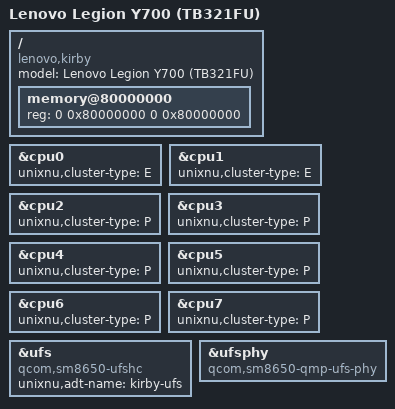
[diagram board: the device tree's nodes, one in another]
/dts-v1/;
/include/ "sm8650.dtsi"

/*
 * Lenovo Legion Y700 (TB321FU) — SM8650 / pineapple / kirby.
 *
 * sm8650.dtsi (devices/UniXNU-sm8650-common/dts) already carries the eight
 * CPUs with timebase-frequency, PSCI and the GIC.  This file adds only what is
 * board specific, so devicetree.generate() can build the ADT sidecar.
 *
 * DRAM: base 0x80000000, size 0x80000000 (2 GiB handoff window).
 *   - board.toml [payload] dram_size = "0x80000000"; generate() rejects a DTS
 *     that disagrees with it.
 *   - MemoryMapLib.c:55 puts the gunyah_hyp reserve at 0x80000000, i.e. the
 *     real start of DRAM rather than an arbitrary number.
 *   - The value is inherited from caihong (same SoC, same IPSW), not guessed.
 */
/ {
    model = "Lenovo Legion Y700 (TB321FU)";
    compatible = "lenovo,kirby", "qcom,sm8650";

    memory@80000000 {
        device_type = "memory";
        reg = <0 0x80000000 0 0x80000000>;
    };
};

/*
 * XNU reads cluster-type as an integer character.  A520 pair is efficiency;
 * the A720 triples and the X4 are performance.  Frequencies and capacities
 * behind that split are recorded at the top of sm8650.dtsi.
 */
&cpu0 { unixnu,cluster-type = "E"; };
&cpu1 { unixnu,cluster-type = "E"; };

&cpu2 { unixnu,cluster-type = "P"; };
&cpu3 { unixnu,cluster-type = "P"; };
&cpu4 { unixnu,cluster-type = "P"; };
&cpu5 { unixnu,cluster-type = "P"; };
&cpu6 { unixnu,cluster-type = "P"; };
&cpu7 { unixnu,cluster-type = "P"; };

/*
 * UFS —— 存储，也是根卷的载体。
 *
 * sm8650.dtsi 里 ufshc@1d84000 和 phy@1d80000 都是 status = "disabled"，
 * 而 devicetree.generate() 只把 enabled 且带 unixnu,adt-name 的节点写进 ADT
 * （scripts/unixnu/devicetree.py:370），所以这里必须打开。
 *
 * 节点名改成 kirby-ufs：patches/xnu/kirby-ufs.patch 的驱动用
 *   SecureDTLookupEntry(NULL, "/kirby-ufs", &node)
 * 按名字取顶层 ADT 节点，再从它的 reg 读控制器窗口，并校验
 * reg[0] == UFS_MMIO_BASE(0x01d84000) 且 reg[1] >= UFS_MMIO_SIZE(0x3000)。
 * dtsi 里默认的 adt-name 是 "ufshc"，不改名驱动就找不到节点。
 *
 * compatible 同时声明 sm8550：SM8650 的 UFS 控制器和 SM8550 同基址同长度，
 * 保留 sm8650 在前，如实说明这块硬件是 SM8650 的。
 */
&ufs {
    status = "okay";
    compatible = "qcom,sm8650-ufshc", "qcom,sm8550-ufshc";
    unixnu,adt-name = "kirby-ufs";
};

&ufsphy {
    status = "okay";
    compatible = "qcom,sm8650-qmp-ufs-phy", "qcom,sm8550-qmp-ufs-phy";
};
